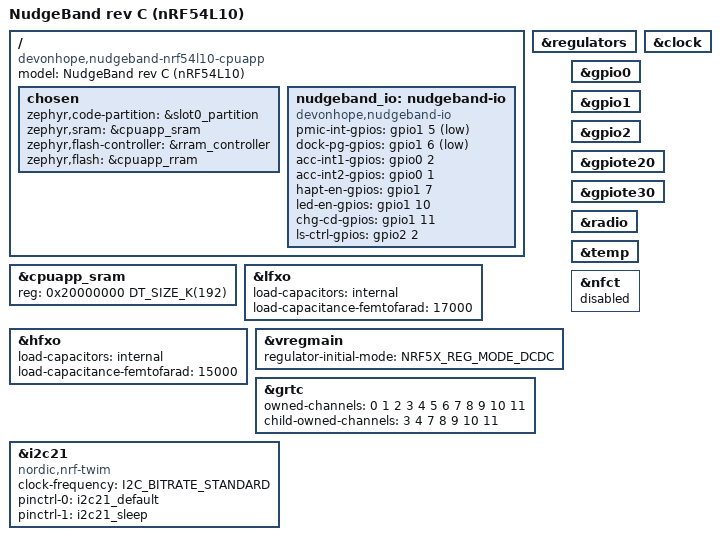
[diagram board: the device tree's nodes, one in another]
/*
 * NudgeBand rev C (hardware/band/rev-c/pcb). Pin map and part notes: that folder's README.md.
 *
 * SPDX-License-Identifier: MIT
 */

/dts-v1/;

#include <nordic/nrf54l10_cpuapp.dtsi>
#include "nudgeband_nrf54l10_cpuapp-pinctrl.dtsi"

/ {
	compatible = "devonhope,nudgeband-nrf54l10-cpuapp";
	model = "NudgeBand rev C (nRF54L10)";

	chosen {
		zephyr,code-partition = &slot0_partition;
		zephyr,sram = &cpuapp_sram;
		zephyr,flash-controller = &rram_controller;
		zephyr,flash = &cpuapp_rram;
	};

	/* Board signals the application drives itself (src/board_io.c). Pin map: band rev C README. */
	nudgeband_io: nudgeband-io {
		compatible = "devonhope,nudgeband-io";
		/* BQ25125 /INT and /PG are open drain with no external pull-ups: use the internal ones. */
		pmic-int-gpios = <&gpio1 5 (GPIO_ACTIVE_LOW | GPIO_PULL_UP)>;
		dock-pg-gpios = <&gpio1 6 (GPIO_ACTIVE_LOW | GPIO_PULL_UP)>; /* low while docked */
		acc-int1-gpios = <&gpio0 2 GPIO_ACTIVE_HIGH>;  /* LIS2DW12 INT1: FIFO watermark */
		acc-int2-gpios = <&gpio0 1 GPIO_ACTIVE_HIGH>;  /* LIS2DW12 INT2: double tap */
		hapt-en-gpios = <&gpio1 7 GPIO_ACTIVE_HIGH>;   /* DRV2605L EN */
		led-en-gpios = <&gpio1 10 GPIO_ACTIVE_HIGH>;   /* IS31FL3193 SDB (R211 pulls low) */
		chg-cd-gpios = <&gpio1 11 GPIO_ACTIVE_HIGH>;   /* BQ25125 /CD: high = I2C, low = Hi-Z */
		ls-ctrl-gpios = <&gpio2 2 GPIO_ACTIVE_HIGH>;   /* BQ25125 LSCTRL: LED supply */
	};

};

&cpuapp_sram {
	status = "okay";
	reg = <0x20000000 DT_SIZE_K(192)>;
	ranges = <0x0 0x20000000 DT_SIZE_K(192)>;
};

/*
 * Crystals use the chip's internal load capacitors (no external caps on the board).
 * X1 32.768 kHz CL 9 pF, X2 32 MHz CL 8 pF: same crystals' CL as the nRF54L15 DK, so its values are
 * the starting point. Check the INTCAP formula against our layout's parasitics (TODO.md, 1.3).
 */
&lfxo {
	load-capacitors = "internal";
	load-capacitance-femtofarad = <17000>;
};

&hfxo {
	load-capacitors = "internal";
	load-capacitance-femtofarad = <15000>;
};

&regulators {
	status = "okay";
};

/* L1 4.7 uH is fitted: run the main regulator as DC/DC. */
&vregmain {
	status = "okay";
	regulator-initial-mode = <NRF5X_REG_MODE_DCDC>;
};

&grtc {
	owned-channels = <0 1 2 3 4 5 6 7 8 9 10 11>;
	child-owned-channels = <3 4 7 8 9 10 11>;
	status = "okay";
};

&clock {
	status = "okay";
};

&gpio0 {
	status = "okay";
};

&gpio1 {
	status = "okay";
};

&gpio2 {
	status = "okay";
};

&gpiote20 {
	status = "okay";
};

&gpiote30 {
	status = "okay";
};

&radio {
	status = "okay";
};

&temp {
	status = "okay";
};

/* NFC pins (P1.02/P1.03) are unused. */
&nfct {
	status = "disabled";
};

&i2c21 {
	status = "okay";
	compatible = "nordic,nrf-twim";
	clock-frequency = <I2C_BITRATE_STANDARD>;
	pinctrl-0 = <&i2c21_default>;
	pinctrl-1 = <&i2c21_sleep>;
	pinctrl-names = "default", "sleep";

	/* Motion sensor: INT1 = FIFO watermark, INT2 = double tap (dismiss) */
	/*
	 * All four parts are driven by small register-level modules in src/ (fixed addresses there):
	 * LIS2DW12 0x19, DRV2605L 0x5A, IS31FL3193 0x68, BQ25125 0x6A. Zephyr's own LIS2DW12 and
	 * DRV2605 drivers can replace two of them later (TODO.md, 2.x).
	 */
};

/* Default 1 MB RRAM partitions (MCUboot slots etc.) */
#include <nordic/nrf54l10_partition.dtsi>
